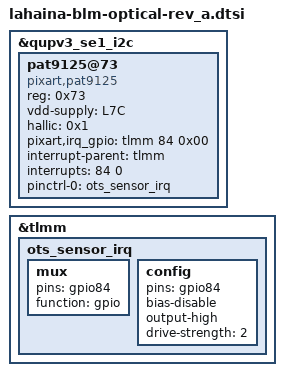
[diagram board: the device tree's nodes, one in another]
/*
 * Copyright (c) 2018, The Linux Foundation. All rights reserved.
 *
 * This program is free software; you can redistribute it and/or modify
 * it under the terms of the GNU General Public License version 2 and
 * only version 2 as published by the Free Software Foundation.
 *
 * This program is distributed in the hope that it will be useful,
 * but WITHOUT ANY WARRANTY; without even the implied warranty of
 * MERCHANTABILITY or FITNESS FOR A PARTICULAR PURPOSE.  See the
 * GNU General Public License for more details.
 */

&qupv3_se1_i2c {
	status = "ok";

	pat9125@73 {
		compatible = "pixart,pat9125";
		reg = <0x73>;

		vdd-supply = <&L7C>;
		hallic = <0x1>;
		pixart,irq_gpio = <&tlmm 84 0x00>;
		interrupt-parent = <&tlmm>;
		interrupts = <84 0>;

		pinctrl-names = "default";
		pinctrl-0 = <&ots_sensor_irq>;
	};
};

&tlmm{
	ots_sensor_irq: ots_sensor_irq {
		mux {
			pins = "gpio84";
			function = "gpio";
		};

		config {
			pins = "gpio84";
			bias-disable;
			output-high;
			drive-strength = <2>;
		};
	};
};
